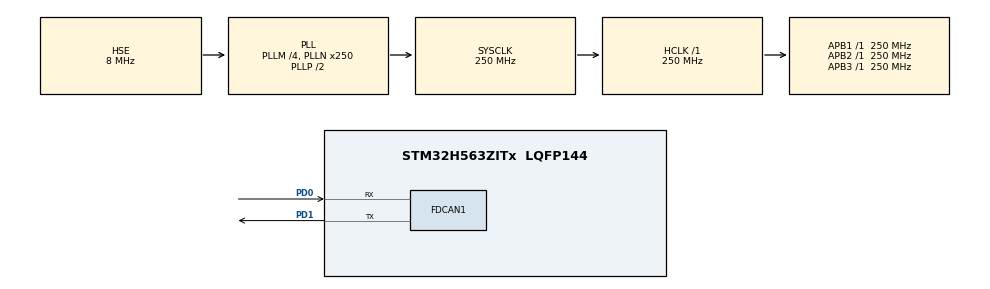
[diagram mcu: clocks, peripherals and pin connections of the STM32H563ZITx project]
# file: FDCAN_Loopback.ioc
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CORTEX_M33_NS.userName=CORTEX_M33
FDCAN1.AutoRetransmission=ENABLE
FDCAN1.CalculateBaudRateNominal=1000000
FDCAN1.CalculateTimeBitNominal=1000
FDCAN1.CalculateTimeQuantumNominal=4.0
FDCAN1.DataPrescaler=5
FDCAN1.DataSyncJumpWidth=5
FDCAN1.DataTimeSeg1=19
FDCAN1.DataTimeSeg2=5
FDCAN1.ExtFiltersNbr=1
FDCAN1.FrameFormat=FDCAN_FRAME_FD_BRS
FDCAN1.Mode=FDCAN_MODE_EXTERNAL_LOOPBACK
FDCAN1.NominalPrescaler=1
FDCAN1.NominalSyncJumpWidth=62
FDCAN1.NominalTimeSeg1=187
FDCAN1.NominalTimeSeg2=62
FDCAN1.StdFiltersNbr=1
FDCAN1.TransmitPause=ENABLE
Mcu.Family=STM32H5
Mcu.Name=STM32H563ZITx
Mcu.Package=LQFP144
NVIC.PriorityGroup=NVIC_PRIORITYGROUP_4
PD0.Mode=FDCAN_Activate
PD0.Signal=FDCAN1_RX
PD1.Mode=FDCAN_Activate
PD1.Signal=FDCAN1_TX
PH0-OSC_IN(PH0).Mode=HSE-DIG-External-Clock-Source
PH0-OSC_IN(PH0).Signal=RCC_OSC_IN
ProjectManager.HeapSize=0x200
ProjectManager.StackSize=0x400
ProjectManager.TargetToolchain=EWARM V9.20
RCC.ADCFreq_Value=250000000
RCC.AHBFreq_Value=250000000
RCC.APB1Freq_Value=250000000
RCC.APB1TimFreq_Value=250000000
RCC.APB2Freq_Value=250000000
RCC.APB2TimFreq_Value=250000000
RCC.APB3Freq_Value=250000000
RCC.CSI_VALUE=4000000
RCC.CortexFreq_Value=250000000
RCC.EPOD_VALUE=8000000
RCC.FDCANClockSelection=RCC_FDCANCLKSOURCE_PLL1Q
RCC.HCLKFreq_Value=250000000
RCC.HSE_VALUE=8000000
RCC.HSI48_VALUE=48000000
RCC.HSI_VALUE=64000000
RCC.LSE_VALUE=32768
RCC.LSIRC_VALUE=32000
RCC.PLLFRACN=0
RCC.PLLM=4
RCC.PLLN=250
RCC.PLLSourceVirtual=RCC_PLL1_SOURCE_HSE
RCC.SYSCLKFreq_VALUE=250000000
RCC.SYSCLKSource=RCC_SYSCLKSOURCE_PLLCLK
RCC.USBFreq_Value=48000000
RCC.VCOOutputFreq_Value=500000000
VP_BOOTPATH_VS_BOOTPATH.Mode=BP_Activate
VP_ICACHE_VS_ICACHE.Mode=DefaultMode
VP_PWR_VS_SECSignals.Mode=Security/Privilege
board=custom

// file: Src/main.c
/* USER CODE BEGIN Header */
/**
  ******************************************************************************
  * @file    FDCAN/FDCAN_Loopback/Src/main.c
  * @author  MCD Application Team
  * @brief   This sample code shows how to configure the FDCAN to adapt to
  *          different CAN bit rates using restricted mode.
  ******************************************************************************
  * @attention
  *
  * Copyright (c) 2023 STMicroelectronics.
  * All rights reserved.
  *
  * This software is licensed under terms that can be found in the LICENSE file
  * in the root directory of this software component.
  * If no LICENSE file comes with this software, it is provided AS-IS.
  *
  ******************************************************************************
  */
/* USER CODE END Header */
#include "main.h"

/* USER CODE BEGIN PD */
#define TX_TIMEOUT               (1000U)   /* Transmission timeout in ms           */

/* Hardware related, can't be changed */
#define NB_RX_FIFO               (3U)      /* Number of RX FIFO Elements available */
/* USER CODE END PD */

/* USER CODE BEGIN PM */
#define COUNTOF(BUFFER) (sizeof((BUFFER)) / sizeof(*(BUFFER)))
/* USER CODE END PM */

FDCAN_HandleTypeDef hfdcan1;

/* USER CODE BEGIN PV */
FDCAN_RxHeaderTypeDef rxHeader;
uint8_t               rxData[12U];
static const uint8_t  txData0[] = {0x10, 0x32, 0x54, 0x76, 0x98, 0x00, 0x11, 0x22, 0x33, 0x44, 0x55, 0x66};
static const uint8_t  txData1[] = {0x55, 0x55, 0x55, 0x55, 0x55, 0x55, 0x55, 0x55, 0x55, 0x55, 0x55, 0x55};
static const uint8_t  txData2[] = {0xFF, 0x00, 0xFF, 0x00, 0xFF, 0x00, 0xFF, 0x00, 0xFF, 0x00, 0xFF, 0x00};

/* USER CODE END PV */

void SystemClock_Config(void);
static void MX_GPIO_Init(void);
static void MX_FDCAN1_Init(void);
static void MX_ICACHE_Init(void);
/* USER CODE BEGIN PFP */
static uint32_t BufferCmp8b(const uint8_t *pBuffer1, const uint8_t *pBuffer2, uint16_t BufferLength);

/* USER CODE END PFP */

int main(void)
{
  /* USER CODE BEGIN 1 */

  /* STM32H5xx HAL library initialization:
       - Systick timer is configured by default as source of time base, but user
             can eventually implement his proper time base source (a general purpose
             timer for example or other time source), keeping in mind that Time base
             duration should be kept 1ms since PPP_TIMEOUT_VALUEs are defined and
             handled in milliseconds basis.
       - Set NVIC Group Priority to 4
       - Low Level Initialization
     */
  /* USER CODE END 1 */

  /* MCU Configuration--------------------------------------------------------*/

  /* Reset of all peripherals, Initializes the Flash interface and the Systick. */
  HAL_Init();

  /* Configure the system clock */
  SystemClock_Config();

  /* USER CODE BEGIN SysInit */
  /* Configure LED1 and LED3 */
  BSP_LED_Init(LED1);
  BSP_LED_Init(LED3);

  /* USER CODE END SysInit */

  /* Initialize all configured peripherals */
  MX_GPIO_Init();
  MX_FDCAN1_Init();
  MX_ICACHE_Init();
  /* USER CODE BEGIN 2 */

  /*##-1 Configure the FDCAN filters ########################################*/

  /* Configure standard ID reception filter to Rx FIFO 0. Only accept ID = FilterID1 */
  FDCAN_FilterTypeDef        sFilterConfig;
  sFilterConfig.IdType       = FDCAN_STANDARD_ID;
  sFilterConfig.FilterIndex  = 0U;
  sFilterConfig.FilterType   = FDCAN_FILTER_DUAL;
  sFilterConfig.FilterConfig = FDCAN_FILTER_TO_RXFIFO0;
  sFilterConfig.FilterID1    = 0x444;
  sFilterConfig.FilterID2    = 0x444; /* For acceptance, MessageID and FilterID1 must match exactly */
  if (HAL_FDCAN_ConfigFilter(&hfdcan1, &sFilterConfig) != HAL_OK)
  {
    Error_Handler();
  }

  /* Configure extended ID reception filter to Rx FIFO 1. Only accept ID between FilterID1 and FilterID2. */
  sFilterConfig.IdType       = FDCAN_EXTENDED_ID;
  sFilterConfig.FilterIndex  = 0U;
  sFilterConfig.FilterType   = FDCAN_FILTER_RANGE_NO_EIDM;
  sFilterConfig.FilterConfig = FDCAN_FILTER_TO_RXFIFO1;
  sFilterConfig.FilterID1    = 0x1111111;
  sFilterConfig.FilterID2    = 0x2222222;
  if (HAL_FDCAN_ConfigFilter(&hfdcan1, &sFilterConfig) != HAL_OK)
  {
    Error_Handler();
  }

  /**
    *  Configure global filter:
    *    - Filter all remote frames with STD and EXT ID
    *    - Reject non matching frames with STD ID and EXT ID
    */
  if (HAL_FDCAN_ConfigGlobalFilter(&hfdcan1,
                                   FDCAN_REJECT, FDCAN_REJECT,
                                   FDCAN_FILTER_REMOTE, FDCAN_FILTER_REMOTE) != HAL_OK)
  {
    Error_Handler();
  }

  /*##-2 Start FDCAN controller (continuous listening CAN bus) ##############*/

  if (HAL_FDCAN_Start(&hfdcan1) != HAL_OK)
  {
    Error_Handler();
  }

  /*##-3 Transmit messages ##################################################*/

  FDCAN_TxHeaderTypeDef        txHeader;

  /* Add message to Tx FIFO */
  txHeader.Identifier          = 0x444;
  txHeader.IdType              = FDCAN_STANDARD_ID;
  txHeader.TxFrameType         = FDCAN_DATA_FRAME;
  txHeader.DataLength          = FDCAN_DLC_BYTES_12;
  txHeader.ErrorStateIndicator = FDCAN_ESI_ACTIVE;
  txHeader.BitRateSwitch       = FDCAN_BRS_ON;
  txHeader.FDFormat            = FDCAN_FD_CAN;
  txHeader.TxEventFifoControl  = FDCAN_STORE_TX_EVENTS;
  txHeader.MessageMarker       = 0x52U;
  if (HAL_FDCAN_AddMessageToTxFifoQ(&hfdcan1, &txHeader, txData0) != HAL_OK)
  {
    Error_Handler();
  }

  /* Add second message to Tx FIFO */
  txHeader.Identifier          = 0x1111112;
  txHeader.IdType              = FDCAN_EXTENDED_ID;
  txHeader.TxFrameType         = FDCAN_DATA_FRAME;
  txHeader.DataLength          = FDCAN_DLC_BYTES_12;
  txHeader.ErrorStateIndicator = FDCAN_ESI_PASSIVE;
  txHeader.BitRateSwitch       = FDCAN_BRS_ON;
  txHeader.FDFormat            = FDCAN_FD_CAN;
  txHeader.TxEventFifoControl  = FDCAN_STORE_TX_EVENTS;
  txHeader.MessageMarker       = 0xCCU;
  if (HAL_FDCAN_AddMessageToTxFifoQ(&hfdcan1, &txHeader, txData1) != HAL_OK)
  {
    Error_Handler();
  }

  /* Add third message to Tx FIFO */
  txHeader.Identifier          = 0x1111113;
  txHeader.IdType              = FDCAN_EXTENDED_ID;
  txHeader.TxFrameType         = FDCAN_DATA_FRAME;
  txHeader.DataLength          = FDCAN_DLC_BYTES_12;
  txHeader.ErrorStateIndicator = FDCAN_ESI_PASSIVE;
  txHeader.BitRateSwitch       = FDCAN_BRS_OFF;
  txHeader.FDFormat            = FDCAN_FD_CAN;
  txHeader.TxEventFifoControl  = FDCAN_STORE_TX_EVENTS;
  txHeader.MessageMarker       = 0xDDU;
  if (HAL_FDCAN_AddMessageToTxFifoQ(&hfdcan1, &txHeader, txData2) != HAL_OK)
  {
    Error_Handler();
  }

  /* Get tick */
  uint32_t tickstart = HAL_GetTick();

  /* Wait transmission complete */
  while (HAL_FDCAN_GetTxFifoFreeLevel(&hfdcan1) != NB_RX_FIFO)
  {
    /* Timeout handling */
    if ((HAL_GetTick() - tickstart) > TX_TIMEOUT)
    {
      Error_Handler();
    }
  }

  /*##-4 Receive messages ###################################################*/

  /* Check one message is received in Rx FIFO 0 */
  if (HAL_FDCAN_GetRxFifoFillLevel(&hfdcan1, FDCAN_RX_FIFO0) != 1U)
  {
    Error_Handler();
  }

  /* Retrieve message from Rx FIFO 0 */
  if (HAL_FDCAN_GetRxMessage(&hfdcan1, FDCAN_RX_FIFO0, &rxHeader, rxData) != HAL_OK)
  {
    Error_Handler();
  }

  /* Compare received RX message to expected data */
  if ((rxHeader.Identifier != 0x444) ||
      (rxHeader.IdType     != FDCAN_STANDARD_ID) ||
      (rxHeader.DataLength != FDCAN_DLC_BYTES_12) ||
      (BufferCmp8b(txData0, rxData, COUNTOF(rxData)) != 0U))
  {
    Error_Handler();
  }

  /* Check two messages are received in Rx FIFO 1 */
  if (HAL_FDCAN_GetRxFifoFillLevel(&hfdcan1, FDCAN_RX_FIFO1) != 2U)
  {
    Error_Handler();
  }

  /* Retrieve message from Rx FIFO 1 */
  if (HAL_FDCAN_GetRxMessage(&hfdcan1, FDCAN_RX_FIFO1, &rxHeader, rxData) != HAL_OK)
  {
    Error_Handler();
  }

  /* Compare received RX message to expected data */
  if ((rxHeader.Identifier != 0x1111112) ||
      (rxHeader.IdType     != FDCAN_EXTENDED_ID) ||
      (rxHeader.DataLength != FDCAN_DLC_BYTES_12) ||
      (BufferCmp8b(txData1, rxData, COUNTOF(rxData)) != 0U))
  {
    Error_Handler();
  }

  /* Retrieve next message from Rx FIFO 1 */
  if (HAL_FDCAN_GetRxMessage(&hfdcan1, FDCAN_RX_FIFO1, &rxHeader, rxData) != HAL_OK)
  {
    Error_Handler();
  }

  /* Compare received RX message to expected data */
  if ((rxHeader.Identifier != 0x1111113) ||
      (rxHeader.IdType     != FDCAN_EXTENDED_ID) ||
      (rxHeader.DataLength != FDCAN_DLC_BYTES_12) ||
      (BufferCmp8b(txData2, rxData, COUNTOF(rxData)) != 0U))
  {
    Error_Handler();
  }

  /* Execution success. Turn ON LED1 */
  BSP_LED_On(LED1);

  /* USER CODE END 2 */

  /* Infinite loop */
  while (1)
  {

  }
}

void SystemClock_Config(void)
{
  RCC_OscInitTypeDef RCC_OscInitStruct = {0};
  RCC_ClkInitTypeDef RCC_ClkInitStruct = {0};

  /** Configure the main internal regulator output voltage
  */
  __HAL_PWR_VOLTAGESCALING_CONFIG(PWR_REGULATOR_VOLTAGE_SCALE0);

  while(!__HAL_PWR_GET_FLAG(PWR_FLAG_VOSRDY)) {}

  /** Initializes the RCC Oscillators according to the specified parameters
  * in the RCC_OscInitTypeDef structure.
  */
  RCC_OscInitStruct.OscillatorType = RCC_OSCILLATORTYPE_HSE;
  RCC_OscInitStruct.HSEState = RCC_HSE_BYPASS_DIGITAL;
  RCC_OscInitStruct.PLL.PLLState = RCC_PLL_ON;
  RCC_OscInitStruct.PLL.PLLSource = RCC_PLL1_SOURCE_HSE;
  RCC_OscInitStruct.PLL.PLLM = 4;
  RCC_OscInitStruct.PLL.PLLN = 250;
  RCC_OscInitStruct.PLL.PLLP = 2;
  RCC_OscInitStruct.PLL.PLLQ = 2;
  RCC_OscInitStruct.PLL.PLLR = 2;
  RCC_OscInitStruct.PLL.PLLRGE = RCC_PLL1_VCIRANGE_1;
  RCC_OscInitStruct.PLL.PLLVCOSEL = RCC_PLL1_VCORANGE_WIDE;
  RCC_OscInitStruct.PLL.PLLFRACN = 0;
  if (HAL_RCC_OscConfig(&RCC_OscInitStruct) != HAL_OK)
  {
    Error_Handler();
  }

  /** Initializes the CPU, AHB and APB buses clocks
  */
  RCC_ClkInitStruct.ClockType = RCC_CLOCKTYPE_HCLK|RCC_CLOCKTYPE_SYSCLK
                              |RCC_CLOCKTYPE_PCLK1|RCC_CLOCKTYPE_PCLK2
                              |RCC_CLOCKTYPE_PCLK3;
  RCC_ClkInitStruct.SYSCLKSource = RCC_SYSCLKSOURCE_PLLCLK;
  RCC_ClkInitStruct.AHBCLKDivider = RCC_SYSCLK_DIV1;
  RCC_ClkInitStruct.APB1CLKDivider = RCC_HCLK_DIV1;
  RCC_ClkInitStruct.APB2CLKDivider = RCC_HCLK_DIV1;
  RCC_ClkInitStruct.APB3CLKDivider = RCC_HCLK_DIV1;

  if (HAL_RCC_ClockConfig(&RCC_ClkInitStruct, FLASH_LATENCY_5) != HAL_OK)
  {
    Error_Handler();
  }
}

static void MX_FDCAN1_Init(void)
{

  hfdcan1.Instance = FDCAN1;
  hfdcan1.Init.ClockDivider = FDCAN_CLOCK_DIV1;
  hfdcan1.Init.FrameFormat = FDCAN_FRAME_FD_BRS;
  hfdcan1.Init.Mode = FDCAN_MODE_EXTERNAL_LOOPBACK;
  hfdcan1.Init.AutoRetransmission = ENABLE;
  hfdcan1.Init.TransmitPause = ENABLE;
  hfdcan1.Init.ProtocolException = DISABLE;
  hfdcan1.Init.NominalPrescaler = 1;
  hfdcan1.Init.NominalSyncJumpWidth = 62;
  hfdcan1.Init.NominalTimeSeg1 = 187;
  hfdcan1.Init.NominalTimeSeg2 = 62;
  hfdcan1.Init.DataPrescaler = 5;
  hfdcan1.Init.DataSyncJumpWidth = 5;
  hfdcan1.Init.DataTimeSeg1 = 19;
  hfdcan1.Init.DataTimeSeg2 = 5;
  hfdcan1.Init.StdFiltersNbr = 1;
  hfdcan1.Init.ExtFiltersNbr = 1;
  hfdcan1.Init.TxFifoQueueMode = FDCAN_TX_FIFO_OPERATION;
  if (HAL_FDCAN_Init(&hfdcan1) != HAL_OK)
  {
    Error_Handler();
  }

}

static void MX_ICACHE_Init(void)
{

  /** Enable instruction cache (default 2-ways set associative cache)
  */
  if (HAL_ICACHE_Enable() != HAL_OK)
  {
    Error_Handler();
  }

}

static void MX_GPIO_Init(void)
{

  /* GPIO Ports Clock Enable */
  __HAL_RCC_GPIOH_CLK_ENABLE();
  __HAL_RCC_GPIOD_CLK_ENABLE();

}

/* USER CODE BEGIN 4 */

/**
  * @brief  Compares two buffers.
  * @param  pBuffer1 buffer to be compared.
  * @param  pBuffer2 buffer to be compared.
  * @param  BufferLength: buffer's length.
  * @retval 0: pBuffer1 is identical to pBuffer2
  * @retval 1: pBuffer1 differs from pBuffer2
  */
static uint32_t BufferCmp8b(const uint8_t *pBuffer1, const uint8_t *pBuffer2, uint16_t BufferLength)
{
  while (BufferLength--)
  {
    if (*pBuffer1 != *pBuffer2)
    {
      return 1U;
    }

    pBuffer1++;
    pBuffer2++;
  }
  return 0U;
}
/* USER CODE END 4 */

void Error_Handler(void)
{
  /* USER CODE BEGIN Error_Handler_Debug */
  /* User can add his own implementation to report the HAL error return state */

  while (1)
  {
    /* Toggle LED3 on */
    BSP_LED_Toggle(LED3);

    /* 1s delay */
    HAL_Delay(1000U);
  }
  /* USER CODE END Error_Handler_Debug */
}
